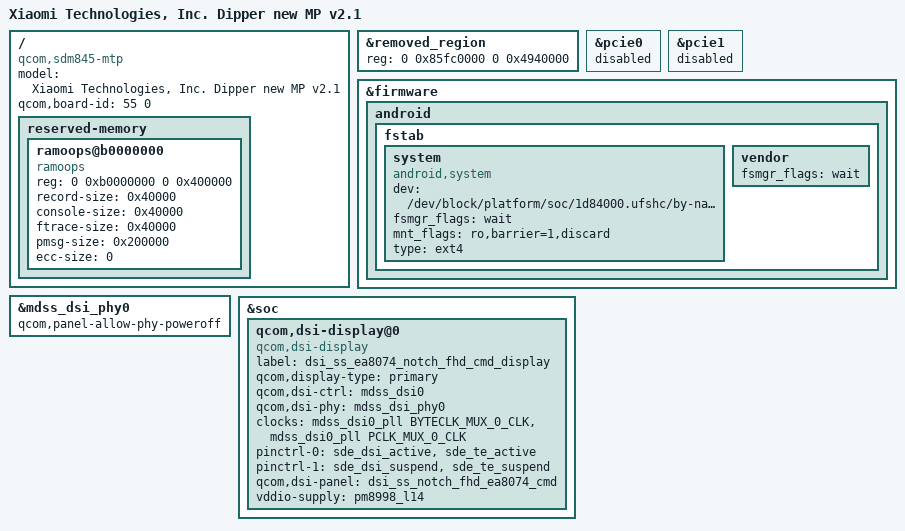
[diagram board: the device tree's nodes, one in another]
// SPDX-License-Identifier: GPL-2.0
/*
 * Copyright (C) 2019 Sultan Alsawaf <sultan@kerneltoast.com>.
 */

/dts-v1/;

#include "sdm845-v2.1.dtsi"
#include "sdm845-sde-display.dtsi"
#include "sdm845-mtp.dtsi"
#include "dsi-panel-ss-notch-fhd-ea8074-cmd.dtsi"

/ {
	model = "Xiaomi Technologies, Inc. Dipper new MP v2.1";
	compatible = "qcom,sdm845-mtp", "qcom,sdm845", "qcom,mtp";
	qcom,board-id = <55 0>;

	reserved-memory {
		ramoops@b0000000 {
			compatible = "ramoops";
			reg = <0 0xb0000000 0 0x400000>;
			record-size = <0x40000>;
			console-size = <0x40000>;
			ftrace-size = <0x40000>;
			pmsg-size = <0x200000>;
			ecc-size = <0>;
		};
	};
};

&removed_region {
	reg = <0 0x85fc0000 0 0x4940000>;
};

&pcie0 {
	status = "disabled";
};

&pcie1 {
	status = "disabled";
};

&firmware {
	android {
		fstab {
			system {
				compatible = "android,system";
				dev = "/dev/block/platform/soc/1d84000.ufshc/by-name/system";
				fsmgr_flags = "wait";
				mnt_flags = "ro,barrier=1,discard";
				type = "ext4";
			};

			vendor {
				fsmgr_flags = "wait";
			};
		};

		/delete-node/ vbmeta;
	};
};

&mdss_dsi_phy0 {
	qcom,panel-allow-phy-poweroff;
};

&soc {
	/delete-node/ qcom,dsi-display@0;

	qcom,dsi-display@0 {
		compatible = "qcom,dsi-display";
		label = "dsi_ss_ea8074_notch_fhd_cmd_display";
		qcom,display-type = "primary";

		qcom,dsi-ctrl = <&mdss_dsi0>;
		qcom,dsi-phy = <&mdss_dsi_phy0>;
		clocks = <&mdss_dsi0_pll BYTECLK_MUX_0_CLK>,
			<&mdss_dsi0_pll PCLK_MUX_0_CLK>;
		clock-names = "mux_byte_clk", "mux_pixel_clk";

		pinctrl-names = "panel_active", "panel_suspend";
		pinctrl-0 = <&sde_dsi_active &sde_te_active>;
		pinctrl-1 = <&sde_dsi_suspend &sde_te_suspend>;

		qcom,dsi-panel = <&dsi_ss_notch_fhd_ea8074_cmd>;
		vddio-supply = <&pm8998_l14>;
	};
};
